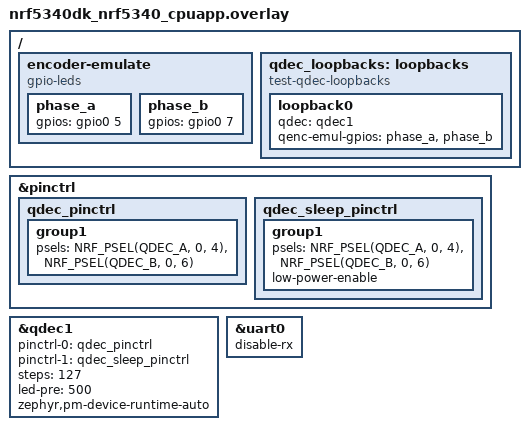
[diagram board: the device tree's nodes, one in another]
/*
 * Copyright 2024 Nordic Semiconductor ASA
 * SPDX-License-Identifier: Apache-2.0
 */

/ {
	encoder-emulate {
		compatible = "gpio-leds";
		phase_a: phase_a {
			/* Arduino A1 */
			gpios = <&gpio0 5 GPIO_ACTIVE_HIGH>;
		};
		phase_b: phase_b {
			/* Arduino A3 */
			gpios = <&gpio0 7 GPIO_ACTIVE_HIGH>;
		};
	};

	qdec_loopbacks: loopbacks {
		compatible = "test-qdec-loopbacks";
		loopback0 {
			qdec = <&qdec1>;
			qenc-emul-gpios = <&phase_a &phase_b>;
		};
	};
};

&pinctrl {
	qdec_pinctrl: qdec_pinctrl {
		group1 {
			psels = <NRF_PSEL(QDEC_A, 0, 4)>,   /* Ardiuno A0 */
				<NRF_PSEL(QDEC_B, 0, 6)>;   /* Arduino A2 */
		};
	};

	qdec_sleep_pinctrl: qdec_sleep_pinctrl {
		group1 {
			psels = <NRF_PSEL(QDEC_A, 0, 4)>,
				<NRF_PSEL(QDEC_B, 0, 6)>;
			low-power-enable;
		};
	};
};

&qdec1 {
	status = "okay";
	pinctrl-0 = <&qdec_pinctrl>;
	pinctrl-1 = <&qdec_sleep_pinctrl>;
	pinctrl-names = "default", "sleep";
	steps = <127>;
	led-pre = <500>;
	zephyr,pm-device-runtime-auto;
};

/* To prevent enabling console receiver. */
&uart0 {
	disable-rx;
};
